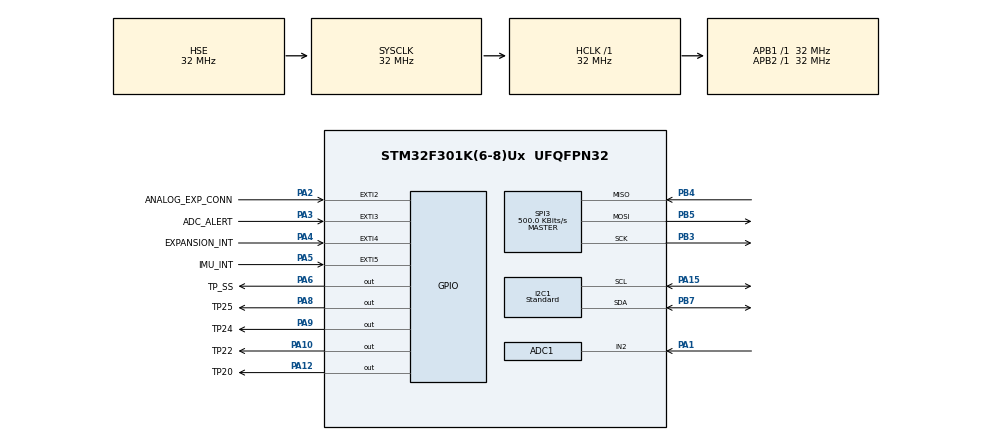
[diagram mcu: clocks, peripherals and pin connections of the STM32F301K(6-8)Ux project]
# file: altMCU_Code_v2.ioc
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ADC1.Channel-18\#ChannelRegularConversion=ADC_CHANNEL_2
ADC1.ClockPrescaler=ADC_CLOCK_SYNC_PCLK_DIV4
ADC1.ContinuousConvMode=DISABLE
ADC1.DMAContinuousRequests=ENABLE
ADC1.EOCSelection=ADC_EOC_SEQ_CONV
ADC1.EnableRegularConversion=ENABLE
ADC1.ExternalTrigConv=ADC_EXTERNALTRIGCONV_T2_TRGO
ADC1.NbrOfConversion=1
ADC1.NbrOfConversionFlag=1
ADC1.Offset-18\#ChannelRegularConversion=0
ADC1.OffsetNumber-18\#ChannelRegularConversion=ADC_OFFSET_NONE
ADC1.Rank-18\#ChannelRegularConversion=1
ADC1.SamplingTime-18\#ChannelRegularConversion=ADC_SAMPLETIME_1CYCLE_5
ADC1.master=1
Dma.ADC1.0.Direction=DMA_PERIPH_TO_MEMORY
Dma.ADC1.0.Instance=DMA1_Channel1
Dma.ADC1.0.MemDataAlignment=DMA_MDATAALIGN_HALFWORD
Dma.ADC1.0.MemInc=DMA_MINC_ENABLE
Dma.ADC1.0.Mode=DMA_CIRCULAR
Dma.ADC1.0.PeriphDataAlignment=DMA_PDATAALIGN_HALFWORD
Dma.ADC1.0.PeriphInc=DMA_PINC_DISABLE
Dma.ADC1.0.Priority=DMA_PRIORITY_LOW
Dma.Request0=ADC1
FREERTOS.Tasks01=defaultTask,24,128,StartDefaultTask,Default,NULL,Dynamic,NULL,NULL
I2C1.I2C_Speed_Mode=I2C_Standard
I2C1.OwnAddress=0x73
I2C1.Timing=0x00707CBB
Mcu.Family=STM32F3
Mcu.Name=STM32F301K(6-8)Ux
Mcu.Package=UFQFPN32
NVIC.ADC1_IRQn=true\:5\:0\:false\:false\:true\:true\:true\:true
NVIC.DMA1_Channel1_IRQn=true\:5\:0\:false\:false\:true\:true\:false\:true
NVIC.I2C1_EV_IRQn=true\:5\:0\:false\:false\:true\:true\:true\:true
NVIC.PriorityGroup=NVIC_PRIORITYGROUP_4
NVIC.SPI3_IRQn=true\:5\:0\:false\:false\:true\:true\:true\:true
NVIC.TIM1_UP_TIM16_IRQn=true\:0\:0\:false\:false\:true\:false\:false\:true
NVIC.TIM2_IRQn=true\:5\:0\:false\:false\:true\:true\:true\:true
NVIC.TimeBase=TIM1_UP_TIM16_IRQn
NVIC.TimeBaseIP=TIM1
PA1.Mode=IN2-Single-Ended
PA1.Signal=ADC1_IN2
PA10.GPIO_Label=TP22
PA10.GPIO_ModeDefaultOutputPP=GPIO_MODE_OUTPUT_PP
PA10.GPIO_PuPd=GPIO_NOPULL
PA10.GPIO_Speed=GPIO_SPEED_FREQ_LOW
PA10.PinState=GPIO_PIN_RESET
PA10.Signal=GPIO_Output
PA12.GPIO_Label=TP20
PA12.GPIO_ModeDefaultOutputPP=GPIO_MODE_OUTPUT_PP
PA12.GPIO_PuPd=GPIO_NOPULL
PA12.GPIO_Speed=GPIO_SPEED_FREQ_LOW
PA12.PinState=GPIO_PIN_RESET
PA12.Signal=GPIO_Output
PA13.Mode=Serial_Wire
PA13.Signal=SYS_JTMS-SWDIO
PA14.Mode=Serial_Wire
PA14.Signal=SYS_JTCK-SWCLK
PA15.GPIO_Mode=GPIO_MODE_AF_OD
PA15.GPIO_PuPdOD=GPIO_NOPULL
PA15.GPIO_Speed=GPIO_SPEED_FREQ_HIGH
PA15.Mode=I2C
PA15.Signal=I2C1_SCL
PA2.GPIO_Label=ANALOG_EXP_CONN
PA2.GPIO_ModeDefaultEXTI=GPIO_MODE_IT_RISING
PA2.GPIO_PuPd=GPIO_NOPULL
PA2.Signal=GPXTI2
PA3.GPIO_Label=ADC_ALERT
PA3.GPIO_ModeDefaultEXTI=GPIO_MODE_IT_RISING
PA3.GPIO_PuPd=GPIO_NOPULL
PA3.Signal=GPXTI3
PA4.GPIO_Label=EXPANSION_INT
PA4.GPIO_ModeDefaultEXTI=GPIO_MODE_IT_RISING
PA4.GPIO_PuPd=GPIO_NOPULL
PA4.Signal=GPXTI4
PA5.GPIO_Label=IMU_INT
PA5.GPIO_ModeDefaultEXTI=GPIO_MODE_IT_RISING
PA5.GPIO_PuPd=GPIO_NOPULL
PA5.Signal=GPXTI5
PA6.GPIO_Label=TP_SS
PA6.GPIO_ModeDefaultOutputPP=GPIO_MODE_OUTPUT_PP
PA6.GPIO_PuPd=GPIO_NOPULL
PA6.GPIO_Speed=GPIO_SPEED_FREQ_LOW
PA6.PinState=GPIO_PIN_SET
PA6.Signal=GPIO_Output
PA8.GPIO_Label=TP25
PA8.GPIO_ModeDefaultOutputPP=GPIO_MODE_OUTPUT_PP
PA8.GPIO_PuPd=GPIO_NOPULL
PA8.GPIO_Speed=GPIO_SPEED_FREQ_LOW
PA8.PinState=GPIO_PIN_RESET
PA8.Signal=GPIO_Output
PA9.GPIO_Label=TP24
PA9.GPIO_ModeDefaultOutputPP=GPIO_MODE_OUTPUT_PP
PA9.GPIO_PuPd=GPIO_NOPULL
PA9.GPIO_Speed=GPIO_SPEED_FREQ_LOW
PA9.PinState=GPIO_PIN_RESET
PA9.Signal=GPIO_Output
PB3.Mode=Full_Duplex_Master
PB3.Signal=SPI3_SCK
PB4.Mode=Full_Duplex_Master
PB4.Signal=SPI3_MISO
PB5.Mode=Full_Duplex_Master
PB5.Signal=SPI3_MOSI
PB7.GPIO_FM7=__NULL
PB7.GPIO_Mode=GPIO_MODE_AF_OD
PB7.GPIO_PuPdOD=GPIO_NOPULL
PB7.GPIO_Speed=GPIO_SPEED_FREQ_HIGH
PB7.Mode=I2C
PB7.Signal=I2C1_SDA
PF0-OSC_IN.Mode=HSE-External-Oscillator
PF0-OSC_IN.Signal=RCC_OSC_IN
PF1-OSC_OUT.Mode=HSE-External-Oscillator
PF1-OSC_OUT.Signal=RCC_OSC_OUT
ProjectManager.HeapSize=0x200
ProjectManager.StackSize=0x400
ProjectManager.TargetToolchain=TrueSTUDIO
RCC.AHBFreq_Value=32000000
RCC.APB1Freq_Value=32000000
RCC.APB1TimFreq_Value=32000000
RCC.APB2Freq_Value=32000000
RCC.APB2TimFreq_Value=32000000
RCC.CortexFreq_Value=32000000
RCC.HCLKFreq_Value=32000000
RCC.HSE_VALUE=32000000
RCC.HSI_VALUE=8000000
RCC.I2c1ClockSelection=RCC_I2C1CLKSOURCE_SYSCLK
RCC.PLLMUL=RCC_PLL_MUL4
RCC.PLLSourceVirtual=RCC_PLLSOURCE_HSE
RCC.SYSCLKFreq_VALUE=32000000
RCC.SYSCLKSourceVirtual=RCC_SYSCLKSOURCE_HSE
SPI3.BaudRatePrescaler=SPI_BAUDRATEPRESCALER_64
SPI3.CLKPhase=SPI_PHASE_1EDGE
SPI3.CLKPolarity=SPI_POLARITY_LOW
SPI3.CalculateBaudRate=500.0 KBits/s
SPI3.DataSize=SPI_DATASIZE_8BIT
SPI3.Direction=SPI_DIRECTION_2LINES
SPI3.Mode=SPI_MODE_MASTER
SPI3.VirtualType=VM_MASTER
TIM2.AutoReloadPreload=TIM_AUTORELOAD_PRELOAD_ENABLE
TIM2.Channel-Output\ Compare1\ No\ Output=TIM_CHANNEL_1
TIM2.Period=9999
TIM2.Prescaler=31999
TIM2.TIM_MasterOutputTrigger=TIM_TRGO_UPDATE
VP_FREERTOS_VS_CMSIS_V2.Mode=CMSIS_V2
VP_SYS_VS_tim1.Mode=TIM1
VP_TIM2_VS_ClockSourceINT.Mode=Internal
VP_TIM2_VS_no_output1.Mode=Output Compare1 No Output
board=custom

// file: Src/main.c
/* USER CODE BEGIN Header */
/**
  ******************************************************************************
  * @file           : main.c
  * @brief          : Main program body
  ******************************************************************************
  * @attention
  *
  * <h2><center>&copy; Copyright (c) 2019 STMicroelectronics.
  * All rights reserved.</center></h2>
  *
  * This software component is licensed by ST under Ultimate Liberty license
  * SLA0044, the "License"; You may not use this file except in compliance with
  * the License. You may obtain a copy of the License at:
  *                             www.st.com/SLA0044
  *
  ******************************************************************************
  */
/* USER CODE END Header */

#include "main.h"
#include "cmsis_os.h"
#include "adc.h"
#include "dma.h"
#include "i2c.h"
#include "spi.h"
#include "tim.h"
#include "gpio.h"

void SystemClock_Config(void);
void MX_FREERTOS_Init(void);

int main(void)
{

  /* MCU Configuration--------------------------------------------------------*/

  /* Reset of all peripherals, Initializes the Flash interface and the Systick. */
  HAL_Init();

  /* Configure the system clock */
  SystemClock_Config();

  /* Initialize all configured peripherals */
  MX_GPIO_Init();
  MX_I2C1_Init();
  MX_SPI3_Init();
  MX_ADC1_Init();
  MX_DMA_Init();
  MX_TIM2_Init();

  /* Call init function for freertos objects (in freertos.c) */
  MX_FREERTOS_Init();

  /* Start scheduler */
  //osKernelStart();

  /* We should never get here as control is now taken by the scheduler */

  /* Infinite loop */
  /* USER CODE BEGIN WHILE */

  //while(HAL_ADCEx_Calibration_Start(&hadc1, ADC_SINGLE_ENDED) != HAL_OK);
  while(HAL_TIM_Base_Start(&htim2) != HAL_OK);

  volatile uint16_t ADC_Data[5] = {0};
  //while(HAL_ADC_Start_DMA(&hadc1, (uint32_t*) ADC_Data, 5) != HAL_OK);
  HAL_ADC_Start_IT(&hadc1);
  while (1)
  {
//	  HAL_Delay(1000);
	  if(HAL_ADC_PollForConversion(&hadc1,100000) == HAL_OK){
		  ADC_Data[0] = HAL_ADC_GetValue(&hadc1);
	  }
    /* USER CODE END WHILE */

  }
}

void SystemClock_Config(void)
{
  RCC_OscInitTypeDef RCC_OscInitStruct = {0};
  RCC_ClkInitTypeDef RCC_ClkInitStruct = {0};
  RCC_PeriphCLKInitTypeDef PeriphClkInit = {0};

  /** Initializes the CPU, AHB and APB busses clocks
  */
  RCC_OscInitStruct.OscillatorType = RCC_OSCILLATORTYPE_HSE;
  RCC_OscInitStruct.HSEState = RCC_HSE_ON;
  RCC_OscInitStruct.HSIState = RCC_HSI_ON;
  RCC_OscInitStruct.PLL.PLLState = RCC_PLL_NONE;
  if (HAL_RCC_OscConfig(&RCC_OscInitStruct) != HAL_OK)
  {
    Error_Handler();
  }
  /** Initializes the CPU, AHB and APB busses clocks
  */
  RCC_ClkInitStruct.ClockType = RCC_CLOCKTYPE_HCLK|RCC_CLOCKTYPE_SYSCLK
                              |RCC_CLOCKTYPE_PCLK1|RCC_CLOCKTYPE_PCLK2;
  RCC_ClkInitStruct.SYSCLKSource = RCC_SYSCLKSOURCE_HSE;
  RCC_ClkInitStruct.AHBCLKDivider = RCC_SYSCLK_DIV1;
  RCC_ClkInitStruct.APB1CLKDivider = RCC_HCLK_DIV1;
  RCC_ClkInitStruct.APB2CLKDivider = RCC_HCLK_DIV1;

  if (HAL_RCC_ClockConfig(&RCC_ClkInitStruct, FLASH_LATENCY_1) != HAL_OK)
  {
    Error_Handler();
  }
  PeriphClkInit.PeriphClockSelection = RCC_PERIPHCLK_I2C1;
  PeriphClkInit.I2c1ClockSelection = RCC_I2C1CLKSOURCE_SYSCLK;
  if (HAL_RCCEx_PeriphCLKConfig(&PeriphClkInit) != HAL_OK)
  {
    Error_Handler();
  }
}

/* USER CODE BEGIN 4 */

///**
//  * @brief  Conversion complete callback in non blocking mode
//  * @param  hadc: ADC handle
//  * @note   This example shows a simple way to report end of conversion
//  *         and get conversion result. You can add your own implementation.
//  * @retval None
//  */
//void HAL_ADC_ConvCpltCallback(ADC_HandleTypeDef *hadc)
//{
//	int i = 0;
//}

/* USER CODE BEGIN 4 */
volatile uint8_t temp = 0;
void HAL_ADC_ConvCpltCallback(ADC_HandleTypeDef* hadc){
  /* This is called after the conversion is completed */
	temp += 1;
}
/* USER CODE END 4 */

void HAL_TIM_PeriodElapsedCallback(TIM_HandleTypeDef *htim)
{
  if (htim->Instance == TIM1) {
    HAL_IncTick();
  }
}

void Error_Handler(void)
{
}

/************************ (C) COPYRIGHT STMicroelectronics *****END OF FILE****/
